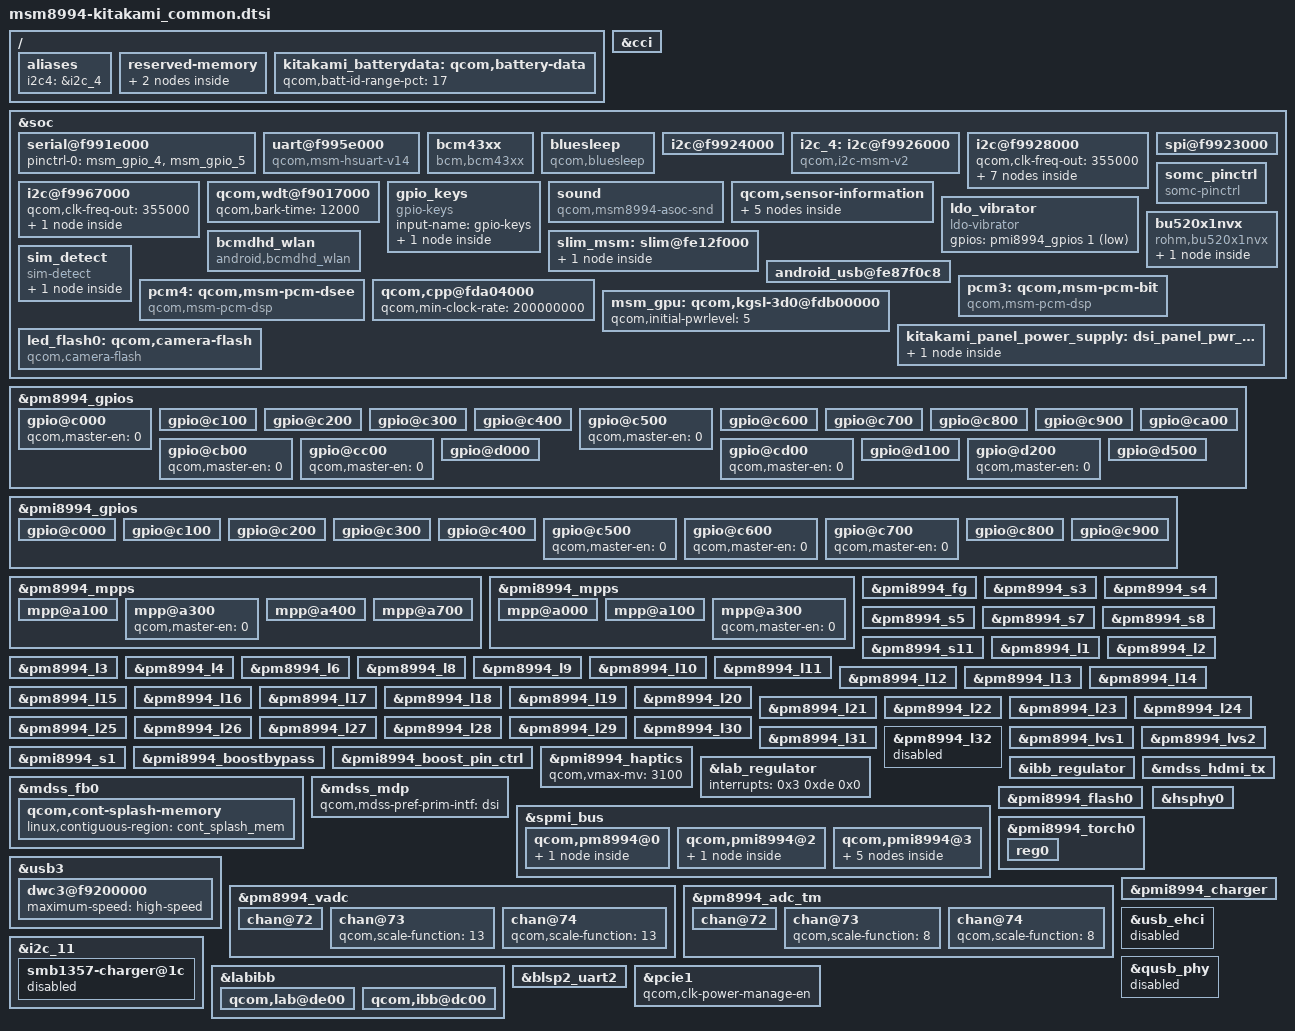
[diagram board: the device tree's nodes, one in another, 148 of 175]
/* arch/arm/boot/dts/qcom/msm8994-kitakami_common.dtsi
 *
 * This program is free software; you can redistribute it and/or modify
 * it under the terms of the GNU General Public License version 2 and
 * only version 2 as published by the Free Software Foundation.
 *
 * This program is distributed in the hope that it will be useful,
 * but WITHOUT ANY WARRANTY; without even the implied warranty of
 * MERCHANTABILITY or FITNESS FOR A PARTICULAR PURPOSE.  See the
 * GNU General Public License for more details.
 */
/*
 * Copyright (C) 2014 Sony Mobile Communications Inc.
 *
 * This program is free software; you can redistribute it and/or modify
 * it under the terms of the GNU General Public License version 2, as
 * published by the Free Software Foundation.
 */

/ {
	aliases {
		i2c4 = &i2c_4;
	};

	reserved-memory {
		fb_mem: fb_region@0 {
			reg = <0 0x40000000 0 0x1000000>;
			label = "fb_mem";
		};

		ramoops_mem: ramoops_region@0 {
			compatible = "removed-dma-pool";
			reg = <0 0x1fe00000 0 0x00200000>;
			no-map;
		};
	};
};

#include "msm8994-kitakami_pinctrl.dtsi"

&cci {
	/delete-node/ qcom,eeprom@0;
	/delete-node/ qcom,eeprom@1;

	/delete-node/ qcom,actuator@0;
	/delete-node/ qcom,actuator@1;

	/delete-node/ qcom,ois@0;

	/delete-node/ qcom,camera@0;
	/delete-node/ qcom,camera@1;
	/delete-node/ qcom,camera@2;
};

&soc {
	/* UART: BLSP2 */
	serial@f991e000 {
		pinctrl-0 = <&msm_gpio_4 &msm_gpio_5>;
		status = "ok";
	};

	/* UART: BLSP8 */
	uart@f995e000 {
		compatible = "qcom,msm-hsuart-v14";
		reg = <0xf995e000 0x1000>,
		      <0xf9944000 0x19000>;
		reg-names = "core_mem", "bam_mem";
		interrupt-names = "core_irq", "bam_irq";
		#address-cells = <0>;
		interrupt-parent = <&blsp2_uart2>;
		interrupts = <0 1>;
		#interrupt-cells = <1>;
		interrupt-map-mask = <0xffffffff>;
		interrupt-map = <0 &intc 0 114 0
				1 &intc 0 239 0>;
		qcom,bam-tx-ep-pipe-index = <2>;
		qcom,bam-rx-ep-pipe-index = <3>;
		pinctrl-names = "default", "sleep";
		pinctrl-0 = <&msm_gpio_45_act &msm_gpio_46_act &msm_gpio_47_act &msm_gpio_48_act>;
		pinctrl-1 = <&msm_gpio_45_sus &msm_gpio_46_sus &msm_gpio_47_sus &msm_gpio_48_sus>;
		qcom,msm-obs;
		status = "ok";
	};

	bcm43xx {
		compatible = "bcm,bcm43xx";
		gpios = <&msm_gpio 91 0x00>, /* BT_REG_ON */
			<&msm_gpio 110 0x00>; /* BT_DEV_WAKE */
		pinctrl-names = "default", "sleep";
		pinctrl-0 = <&msm_gpio_91_act &msm_gpio_110_act>;
		pinctrl-1 = <&msm_gpio_91_sus &msm_gpio_110_sus>;
	};

	bluesleep {
		compatible = "qcom,bluesleep";
		bt_ext_wake = <&msm_gpio 110 0>;
		bt_host_wake = <&msm_gpio 111 0>;
		bt_reg_on = <&msm_gpio 91 0>;
		interrupt-parent = <&msm_gpio>;
		interrupts = <111 0>;
		interrupt-names = "host_wake";
		pinctrl-names = "default", "sleep";
		pinctrl-0 = <&msm_gpio_91_act &msm_gpio_110_act &msm_gpio_111_act>;
		pinctrl-1 = <&msm_gpio_91_sus &msm_gpio_110_sus &msm_gpio_111_sus>;
	};

	/* I2C : BLSP2 */
	i2c@f9924000 {
		qcom,clk-freq-out = <355000>;
		qcom,disable-dma;
		status = "ok";

		/delete-node/ synaptics@20;
	};

	/* I2C : BLSP4 */
	i2c_4: i2c@f9926000 {
		compatible = "qcom,i2c-msm-v2";
		#address-cells = <1>;
		#size-cells = <0>;
		reg-names = "qup_phys_addr", "bam_phys_addr";
		reg = <0xf9926000 0x1000>,
		      <0xf9904000 0x19000>;
		interrupt-names = "qup_irq", "bam_irq";
		interrupts = <0 98 0>, <0 238 0>;
		qcom,clk-freq-out = <355000>;
		qcom,clk-freq-in  = <19200000>;
		clock-names = "iface_clk", "core_clk";
		clocks = <&clock_gcc clk_gcc_blsp1_ahb_clk>,
			 <&clock_gcc clk_gcc_blsp1_qup4_i2c_apps_clk>;

		pinctrl-names = "i2c_active", "i2c_sleep";
		pinctrl-0 = <&i2c_4_active>;
		pinctrl-1 = <&i2c_4_sleep>;
		qcom,noise-rjct-scl = <0>;
		qcom,noise-rjct-sda = <0>;
		qcom,bam-pipe-idx-cons = <18>;
		qcom,bam-pipe-idx-prod = <19>;
		qcom,master-id = <86>;
		status = "ok";
	};

	/* I2C : BLSP6 */
	i2c@f9928000 {
		qcom,clk-freq-out = <355000>;
		status = "ok";
		synaptics_clearpad@2c {
			compatible = "synaptics,clearpad";
			reg = <0x2c>;
			interrupt-parent = <&msm_gpio>;
			interrupts = <42 0x2>;
			touch_vdd-supply = <&pm8994_l22>;
			touch_vio-supply = <&pm8994_s4>;
			synaptics,irq_gpio = <&msm_gpio 42 0x00>;
			synaptics,reset_gpio = <&msm_gpio 109 0x00>;
			chip_id = <0x38>;
			num_sensor_rx = <29>;
			num_sensor_tx = <16>;
			flip_config = <0>;
			default_reporting_mode = <0>;
			rezero_on_init = <0>;
			reset_on_init = <1>;
			force_cal_on_resume = <1>;
			charger_supported = <0>;
			pen_supported = <0>;
			glove_supported = <1>;
			cover_supported = <1>;
			touch_pressure_enabled = <1>;
			touch_size_enabled = <0>;
			touch_orientation_enabled = <0>;
			preset_x_max = <1079>;
			preset_y_max = <1919>;
			preset_n_fingers = <10>;
			synaptics,use-pinctrl;
			pinctrl-names = "irq_gpio-active", "irq_gpio-suspend",
					"reset_gpio-active", "reset_gpio-suspend",
					"reset_gpio-reset";
			pinctrl-0 = <&msm_gpio_42_act>;
			pinctrl-1 = <&msm_gpio_42_sus>;
			pinctrl-2 = <&msm_gpio_109_act>;
			pinctrl-3 = <&msm_gpio_109_sus>;
			pinctrl-4 = <&msm_gpio_109_res>;
			delay_on_hw_reset = <0>;
			delay_after_hw_reset = <200>;
			delay_on_gpio_reset = <400>;
			wakeup_gesture_supported = <1>;
			wakeup_gesture_large_panel = <0>;
			wakeup_gesture_lpm_disabled = <1>;
			wakeup_gesture_timeout = <2000>;
			wakeup_gesture {
				double_tap {
					gesture_code = <0x0003>;
					event_00 {
						type = <2>; /* LOG */
						message = "=== DOUBLE TAP ===";
					};
					event_01 {
						type = <1>; /* KEY */
						code = <116>; /* KEY_POWER */
						down = <1>;
					};
					event_02 {
						type = <1>; /* KEY */
						code = <116>; /* KEY_POWER */
						down = <0>;
					};
					event_03 {
						type = <99>; /* END */
					};
				};
			};
		};

		/delete-node/ nfc-nci@e;
	};

	/* I2C : BLSP11 */
	i2c@f9967000 {
		qcom,clk-freq-out = <355000>;
		status = "ok";

		sii8620@72 {
			compatible = "qcom,mhl-sii8620";
			reg = <0x72>;
			interrupt-parent = <&msm_gpio>;
			mhl-intr-gpio = <&msm_gpio 57 0>;
			mhl-rst-gpio = <&msm_gpio 62 0>;
			mhl-fw-wake-gpio = <&msm_gpio 31 0>;
			mhl-switch-sel-1-gpio = <&pmi8994_gpios 9 0>;
			mhl-switch-sel-2-gpio = <&pmi8994_gpios 10 0>;
			mhl-clk-gpio = <&pm8994_gpios 17 0>;
			clocks = <&clock_rpm clk_div_clk3>;
			clock-names = "mhl_clk";
			mhl_vcc-supply = <&pm8994_l25>;
			qcom,hdmi-tx-map = <&mdss_hdmi_tx>;
		};

		/delete-node/ silabs4705@11;
	};

	/* SPI : BLSP1 */
	spi@f9923000 {
		pinctrl-0 = <&spi0_default>;
		pinctrl-1 = <&spi0_sleep>;
		qcom,shared;
		status = "ok";
	};

	qcom,wdt@f9017000 {
		qcom,bark-time = <12000>;
	};

	gpio_keys {
		compatible = "gpio-keys";
		input-name = "gpio-keys";

		vol_dn {
			label = "volume_down";
			gpios = <&pm8994_gpios 2 0x1>;
			linux,input-type = <1>;
			linux,code = <114>;
			gpio-key,wakeup;
			debounce-interval = <15>;
		};
	};

	sound {
		compatible = "qcom,msm8994-asoc-snd";
		qcom,model = "msm8994-tomtom-snd-card";
		reg = <0xfe034000 0x4>,
		      <0xfe035000 0x4>,
		      <0xfe036000 0x4>,
		      <0xfe037000 0x4>;
		reg-names = "lpaif_pri_mode_muxsel",
			    "lpaif_sec_mode_muxsel",
			    "lpaif_tert_mode_muxsel",
			    "lpaif_quat_mode_muxsel";

		qcom,audio-routing =
			"AIF4 VI", "MCLK",
			"RX_BIAS", "MCLK",
			"LDO_H", "MCLK",
			"MADINPUT", "MCLK",
			"AMIC1", "LDO_H",
			"LDO_H", "AHC ISNS",
			"AMIC2", "MIC BIAS2 External",
			"MIC BIAS2 External", "Headset Mic",
			"MIC BIAS2 External", "ANCRight Headset Mic",
			"AMIC3", "MIC BIAS3 External",
			"MIC BIAS3 External", "ANCLeft Headset Mic",
			"AMIC4", "LDO_H",
			"LDO_H", "AHC VSNS",
			"DMIC1", "MIC BIAS1 External",
			"MIC BIAS1 External", "Digital Mic1",
			"DMIC2", "MIC BIAS1 External",
			"MIC BIAS1 External", "Digital Mic2";
		clock-names = "osr_clk";
		clocks = <&clock_rpm clk_div_clk1>;
		qcom,cdc-mclk-gpios = <&pm8994_gpios 15 0>;
		qcom,tomtom-mclk-clk-freq = <9600000>;
		pinctrl-names = "sleep",
				"auxpcm-active",
				"mi2s-active",
				"active";
		pinctrl-0 = <&pri_mi2s_sleep>, <&pri_mi2s_sd0_sleep>,
				<&sec_aux_pcm_sleep>, <&sec_aux_pcm_din_sleep>;
		pinctrl-1 = <&pri_mi2s_sleep>, <&pri_mi2s_sd0_sleep>,
				<&sec_aux_pcm_active>, <&sec_aux_pcm_din_active>;
		pinctrl-2 = <&pri_mi2s_active>, <&pri_mi2s_sd0_active>,
				<&sec_aux_pcm_sleep>, <&sec_aux_pcm_din_sleep>;
		pinctrl-3 = <&pri_mi2s_active>, <&pri_mi2s_sd0_active>,
				<&sec_aux_pcm_active>, <&sec_aux_pcm_din_active>;
		qcom,ear-en-gpios = <&pm8994_gpios 22 0>;
		qcom,mbhc-audio-jack-type = "5-pole-jack";

		qcom,hdmi-audio-rx;
	};

	qcom,sensor-information {
		/* msm_therm */
		qcom,sensor-information@17 {
			qcom,scaling-factor = <10>;
		};

		/* emmc_therm */
		qcom,sensor-information@18 {
			qcom,scaling-factor = <10>;
		};

		/* quiet_therm */
		qcom,sensor-information@21 {
			qcom,alias-name = "bl_therm";
		};

		sensor_information100: qcom,sensor-information@100 {
			qcom,sensor-type = "adc";
			qcom,sensor-name = "bms";
			qcom,alias-name = "batt_therm";
			qcom,scaling-factor = <1000>;
		};

		sensor_information101: qcom,sensor-information@101 {
			qcom,sensor-type = "adc";
			qcom,sensor-name = "xo_therm";
		};
	};

	ldo_vibrator {
		compatible = "ldo-vibrator";
		gpios = <&pmi8994_gpios 1 1>;
	};

	bcmdhd_wlan {
		compatible = "android,bcmdhd_wlan";
		gpios = <&msm_gpio 113 0x00>, /* WL_REG_ON */
			<&msm_gpio 108 0x00>; /* WL_HOST_WAKE */
		pinctrl-names = "default", "sleep";
		pinctrl-0 = <&msm_gpio_113_act &msm_gpio_108_act>;
		pinctrl-1 = <&msm_gpio_113_sus &msm_gpio_108_sus>;
		wlan-pci-number = <1>;
	};

	somc_pinctrl: somc_pinctrl {
		compatible = "somc-pinctrl";
		pinctrl-names = "platform_common_default",
				"product_common_default",
				"variant_default";
		pinctrl-0 = <&msm_gpio_0 &msm_gpio_1 &msm_gpio_2 &msm_gpio_3 &msm_gpio_4
			     &msm_gpio_5 &msm_gpio_6 &msm_gpio_7 &msm_gpio_8 &msm_gpio_9
			     &msm_gpio_10 &msm_gpio_11 &msm_gpio_12 &msm_gpio_13 &msm_gpio_14
			     &msm_gpio_15 &msm_gpio_16 &msm_gpio_17 &msm_gpio_18 &msm_gpio_19
			     &msm_gpio_20 &msm_gpio_21 &msm_gpio_22 &msm_gpio_23 &msm_gpio_24
			     &msm_gpio_25 &msm_gpio_26 &msm_gpio_27 &msm_gpio_28 &msm_gpio_29
			     &msm_gpio_30 &msm_gpio_31 &msm_gpio_38 &msm_gpio_39 &msm_gpio_40
			     &msm_gpio_41 &msm_gpio_42 &msm_gpio_43 &msm_gpio_44 &msm_gpio_45
			     &msm_gpio_46 &msm_gpio_47 &msm_gpio_48 &msm_gpio_52 &msm_gpio_53
			     &msm_gpio_54 &msm_gpio_55 &msm_gpio_56 &msm_gpio_57 &msm_gpio_58
			     &msm_gpio_59 &msm_gpio_60 &msm_gpio_61 &msm_gpio_62 &msm_gpio_63
			     &msm_gpio_64 &msm_gpio_69 &msm_gpio_74 &msm_gpio_75 &msm_gpio_76
			     &msm_gpio_77 &msm_gpio_78 &msm_gpio_83 &msm_gpio_84 &msm_gpio_85
			     &msm_gpio_86 &msm_gpio_87 &msm_gpio_88 &msm_gpio_89 &msm_gpio_90
			     &msm_gpio_91 &msm_gpio_92 &msm_gpio_93 &msm_gpio_94 &msm_gpio_95
			     &msm_gpio_96 &msm_gpio_100 &msm_gpio_102 &msm_gpio_103 &msm_gpio_104
			     &msm_gpio_105 &msm_gpio_106 &msm_gpio_107 &msm_gpio_108 &msm_gpio_109
			     &msm_gpio_110 &msm_gpio_111 &msm_gpio_112 &msm_gpio_113 &msm_gpio_114
			     &msm_gpio_122>;


		/* If product common default setting is needed,
		   fill pinctrl-1 value in <product>_common.dtsi */
		pinctrl-1 = <>;

		/* If variant specific default setting is needed,
		   fill pinctrl-2 value in <variant>.dtsi */
		pinctrl-2 = <>;
	};

	bu520x1nvx {
		compatible = "rohm,bu520x1nvx";

		acc_cover {
			label = "lid";
			gpios = <&pm8994_gpios 11 0x1>;
			lid-pin = <1>;
			debounce-interval = <50>;
		};
	};
	slim_msm: slim@fe12f000 {
		tomtom_codec {
			qcom,cdc-dmic-sample-rate = <2400000>;
			qcom,cdc-dmic_clk_drv_strength = <2>;
		};
	};

	android_usb@fe87f0c8 {
		/delete-property/ qcom,android-usb-uicc-nluns;
	};

	sim_detect {
		compatible = "sim-detect";
		interrupt-parent = <&msm_gpio>;
		interrupts = <100 0>;

		sim1_det {
			label = "sim-detection";
			pinctrl-names = "tlmm_gpio_key_active",
					"tlmm_gpio_key_suspend";
			pinctrl-0 = <&msm_gpio_100_act>;
			pinctrl-1 = <&msm_gpio_100_sus>;
			gpios = <&msm_gpio 100 0x0>;
			debounce-interval = <10>;
		};
	};
	pcm3: qcom,msm-pcm-bit {
		compatible = "qcom,msm-pcm-dsp";
		qcom,msm-pcm-dsp-id = <3>;
		qcom,msm-pcm-bit;
	};

	pcm4: qcom,msm-pcm-dsee {
		compatible = "qcom,msm-pcm-dsp";
		qcom,msm-pcm-dsp-id = <4>;
		qcom,msm-pcm-bit;
	};
	qcom,cpp@fda04000 {
		qcom,min-clock-rate = <200000000>;
	};

        msm_gpu: qcom,kgsl-3d0@fdb00000 {
                qcom,initial-pwrlevel = <3>;
	};

	kitakami_panel_power_supply: dsi_panel_pwr_supply {
		#address-cells = <1>;
		#size-cells = <0>;
		qcom,panel-supply-entry@0 {
			reg = <0>;
			qcom,supply-name = "vdd";
			qcom,supply-min-voltage = <1800000>;
			qcom,supply-max-voltage = <1800000>;
			qcom,supply-enable-load = <100000>;
			qcom,supply-disable-load = <100>;
			qcom,supply-post-on-sleep = <5>;
		};
/*
		qcom,panel-supply-entry@1 {
			reg = <1>;
			qcom,supply-name = "lab";
			qcom,supply-min-voltage = <5100000>;
			qcom,supply-max-voltage = <5100000>;
			qcom,supply-enable-load = <100000>;
			qcom,supply-disable-load = <100>;
		};

		qcom,panel-supply-entry@2 {
			reg = <2>;
			qcom,supply-name = "ibb";
			qcom,supply-min-voltage = <5100000>;
			qcom,supply-max-voltage = <5100000>;
			qcom,supply-enable-load = <100000>;
			qcom,supply-disable-load = <100>;
			qcom,supply-post-on-sleep = <20>;
		};*/
	};

	led_flash0: qcom,camera-flash {
		cell-index = <0>;
		compatible = "qcom,camera-flash";
		qcom,flash-type = <1>;
		qcom,flash-source = <&pmi8994_flash0 &pmi8994_flash1>;
		qcom,torch-source = <&pmi8994_torch0 &pmi8994_torch1>;
	};

	/delete-node/ qcom,cnss@06300000;
};

&pm8994_gpios {
	/* GPIO_1: NC */
	gpio@c000 {
		qcom,master-en = <0>;		/* Disable */
		status = "ok";
	};

	/* GPIO_2: VOL_DOWN_N */
	gpio@c100 {
		qcom,src-sel = <0>;		/* GPIO */
		qcom,mode = <0>;		/* In */
		qcom,vin-sel = <2>;		/* S4 */
		qcom,pull = <0>;		/* PU */
		qcom,master-en = <1>;		/* Enable */
		status = "ok";
	};

	/* GPIO_3: VOL_UP_N */
	gpio@c200 {
		qcom,src-sel = <0>;		/* GPIO */
		qcom,mode = <0>;		/* In */
		qcom,vin-sel = <2>;		/* S4 */
		qcom,pull = <0>;		/* PU */
		qcom,master-en = <1>;		/* Enable */
		status = "ok";
	};

	/* GPIO_4: SNAPSHOT_N */
	gpio@c300 {
		qcom,src-sel = <0>;		/* GPIO */
		qcom,mode = <0>;		/* In */
		qcom,vin-sel = <2>;		/* S4 */
		qcom,pull = <0>;		/* PU */
		qcom,master-en = <1>;		/* Enable */
		status = "ok";
	};

	/* GPIO_5: FOCUS_N */
	gpio@c400 {
		qcom,src-sel = <0>;		/* GPIO */
		qcom,mode = <0>;		/* In */
		qcom,vin-sel = <2>;		/* S4 */
		qcom,pull = <0>;		/* PU */
		qcom,master-en = <1>;		/* Enable */
		status = "ok";
	};

	/* GPIO_6: NC */
	gpio@c500 {
		qcom,master-en = <0>;		/* Disable */
		status = "ok";
	};

	/* GPIO_7: NFC_VEN */
	gpio@c600 {
		qcom,src-sel = <0>;		/* GPIO */
		qcom,mode = <1>;		/* Out */
		qcom,output-type = <0>;		/* CMOS */
		qcom,vin-sel = <2>;		/* S4 */
		qcom,out-strength = <1>;	/* Low */
		qcom,invert = <0>;		/* Low */
		qcom,master-en = <1>;		/* Enable */
		status = "ok";
	};

	/* GPIO_8: SD_CARD_DET1_N */
	gpio@c700 {
		qcom,src-sel = <0>;		/* GPIO */
		qcom,mode = <0>;		/* In */
		qcom,vin-sel = <2>;		/* S4 */
		qcom,pull = <5>;		/* NP */
		qcom,master-en = <1>;		/* Enable */
		status = "ok";
	};

	/* GPIO_9: TUNER_INT */
	gpio@c800 {
		qcom,src-sel = <0>;		/* GPIO */
		qcom,mode = <0>;		/* In */
		qcom,vin-sel = <2>;		/* S4 */
		qcom,pull = <4>;		/* PD */
		qcom,master-en = <1>;		/* Enable */
		status = "ok";
	};

	/* GPIO_10: NFC_CLK_REQ */
	gpio@c900 {
		qcom,src-sel = <0>;		/* GPIO */
		qcom,mode = <0>;		/* In */
		qcom,vin-sel = <2>;		/* S4 */
		qcom,pull = <4>;		/* PD */
		qcom,master-en = <1>;		/* Enable */
		status = "ok";
	};

	/* GPIO_11: ACC_COVER_OPEN */
	gpio@ca00 {
		qcom,src-sel = <0>;		/* GPIO */
		qcom,mode = <0>;		/* In */
		qcom,vin-sel = <2>;		/* S4 */
		qcom,pull = <0>;		/* PU */
		qcom,master-en = <1>;		/* Enable */
		status = "ok";
	};

	/* GPIO_12: NC */
	gpio@cb00 {
		qcom,master-en = <0>;		/* Disable */
		status = "ok";
	};

	/* GPIO_13: NC */
	gpio@cc00 {
		qcom,master-en = <0>;		/* Disable */
		status = "ok";
	};

	/* GPIO_14: NC */
	gpio@cd00 {
		qcom,master-en = <0>;		/* Disable */
		status = "ok";
	};

	/* GPIO_15: PM_DIVCLK1 */
	/* Follow QCT */

	/* GPIO_16: PMI_CLK */
	/* Follow QCT */

	/* GPIO_17: DIVCLK3 */
	gpio@d000 {
		qcom,src-sel = <2>;		/* SPECIAL_FUNCTION1 */
		qcom,mode = <1>;		/* Out */
		qcom,output-type = <0>;		/* CMOS */
		qcom,vin-sel = <2>;		/* S4 */
		qcom,out-strength = <1>;	/* Low */
		qcom,invert = <0>;		/* Low */
		qcom,master-en = <1>;		/* Enable */
		status = "ok";
	};

	/* GPIO_18: WL_SLEEP_CLK */
	gpio@d100 {
		qcom,src-sel = <3>;		/* SPECIAL_FUNCTION2 */
		qcom,mode = <1>;		/* Out */
		qcom,output-type = <0>;		/* CMOS */
		qcom,vin-sel = <2>;		/* S4 */
		qcom,out-strength = <1>;	/* Low */
		qcom,invert = <0>;		/* Low */
		qcom,master-en = <1>;		/* Enable */
		status = "ok";
	};

	/* GPIO_19: NC */
	gpio@d200 {
		qcom,master-en = <0>;		/* Disable */
		status = "ok";
	};

	/* GPIO_20: PMI_SPON */
	/* Follow QCT */

	/* GPIO_21: BUA_PMI8994 */
	/* Follow QCT */

	/* GPIO_22: EAR_EN */
	gpio@d500 {
		qcom,src-sel = <0>;		/* GPIO */
		qcom,mode = <1>;		/* Out */
		qcom,output-type = <0>;		/* CMOS */
		qcom,vin-sel = <2>;		/* S4 */
		qcom,out-strength = <1>;	/* Low */
		qcom,invert = <0>;		/* Low */
		qcom,master-en = <1>;		/* Enable */
		status = "ok";
	};
};

&pmi8994_gpios {
	/* GPIO_1: VIB_LDO_EN */
	gpio@c000 {
		qcom,src-sel = <0>;		/* GPIO */
		qcom,mode = <1>;		/* Out */
		qcom,output-type = <0>;		/* CMOS */
		qcom,vin-sel = <2>;		/* S4 */
		qcom,out-strength = <1>;	/* Low */
		qcom,invert = <0>;		/* Low */
		qcom,master-en = <1>;		/* Enable */
		status = "ok";
	};

	/* GPIO_2: CHG_PATH_PRI */
	gpio@c100 {
		qcom,src-sel = <0>;		/* GPIO */
		qcom,mode = <0>;		/* In */
		qcom,vin-sel = <2>;		/* S4 */
		qcom,pull = <5>;		/* NP */
		qcom,master-en = <1>;		/* Enable */
		status = "ok";
	};

	/* GPIO_3: TUNER_ANT_SW_EN */
	gpio@c200 {
		qcom,src-sel = <0>;		/* GPIO */
		qcom,mode = <1>;		/* Out */
		qcom,output-type = <0>;		/* CMOS */
		qcom,vin-sel = <2>;		/* S4 */
		qcom,out-strength = <1>;	/* Low */
		qcom,invert = <0>;		/* Low */
		qcom,master-en = <1>;		/* Enable */
		status = "ok";
	};

	/* GPIO_4: TUNER_ANT_SW1 */
	gpio@c300 {
		qcom,src-sel = <0>;		/* GPIO */
		qcom,mode = <1>;		/* Out */
		qcom,output-type = <0>;		/* CMOS */
		qcom,vin-sel = <2>;		/* S4 */
		qcom,out-strength = <1>;	/* Low */
		qcom,invert = <1>;		/* High */
		qcom,master-en = <1>;		/* Enable */
		status = "ok";
	};

	/* GPIO_5: USB3OTG_VBUS_EN */
	gpio@c400 {
		qcom,src-sel = <0>;		/* GPIO */
		qcom,mode = <1>;		/* Out */
		qcom,output-type = <0>;		/* CMOS */
		qcom,vin-sel = <2>;		/* S4 */
		qcom,out-strength = <1>;	/* Low */
		qcom,invert = <0>;		/* Low */
		qcom,master-en = <1>;		/* Enable */
		status = "ok";
	};

	/* GPIO_6: NC */
	gpio@c500 {
		qcom,master-en = <0>;		/* Disable */
		status = "ok";
	};

	/* GPIO_7: NC */
	gpio@c600 {
		qcom,master-en = <0>;		/* Disable */
		status = "ok";
	};

	/* GPIO_8: NC */
	gpio@c700 {
		qcom,master-en = <0>;		/* Disable */
		status = "ok";
	};

	/* GPIO_9: MHL_SWITCH_SEL_1 */
	gpio@c800 {
		qcom,src-sel = <0>;		/* GPIO */
		qcom,mode = <1>;		/* Out */
		qcom,output-type = <0>;		/* CMOS */
		qcom,vin-sel = <2>;		/* S4 */
		qcom,out-strength = <1>;	/* Low */
		qcom,invert = <0>;		/* Low */
		qcom,master-en = <1>;		/* Enable */
		status = "ok";
	};

	/* GPIO_10: MHL_SWITCH_SEL_2 */
	gpio@c900 {
		qcom,src-sel = <0>;		/* GPIO */
		qcom,mode = <1>;		/* Out */
		qcom,output-type = <0>;		/* CMOS */
		qcom,vin-sel = <2>;		/* S4 */
		qcom,out-strength = <1>;	/* Low */
		qcom,invert = <0>;		/* Low */
		qcom,master-en = <1>;		/* Enable */
		status = "ok";
	};
};

&pm8994_mpps {
	/* MPP_1: SDC_UIM_VBIAS */
	/* Follow QCT */

	/* MPP_2: LCD_ID_ADC */
	mpp@a100 {
		qcom,mode = <4>;		/* AIN */
		qcom,ain-route = <1>;		/* AMUX 6 */
		qcom,master-en = <1>;		/* Enable */
		status = "ok";
	};

	/* MPP_3: VREF_DACX */
	/* Follow QCT */

	/* MPP_4: NC */
	mpp@a300 {
		qcom,master-en = <0>;		/* Disable */
		status = "ok";
	};

	/* MPP_5: USB_THERM */
	mpp@a400 {
		qcom,mode = <4>;		/* AIN */
		qcom,ain-route = <0>;		/* AMUX 5 */
		qcom,master-en = <1>;		/* Enable */
		status = "ok";
	};

	/* MPP_6: AUX_PMIC_VSEL */
	/* Follow QCT */

	/* MPP_7: AUX_PMIC_PON */
	/* Follow QCT */

	/* MPP_8: RF_ID */
	mpp@a700 {
		qcom,mode = <4>;		/* AIN */
		qcom,ain-route = <3>;		/* AMUX 8 */
		qcom,master-en = <1>;		/* Enable */
		status = "ok";
	};
};

&pmi8994_mpps {
	/* MPP_1: USB_ID_DISCHG */
	mpp@a000 {
		qcom,mode = <0>;		/* DIN */
		qcom,vin-sel = <0>;		/* VPH */
		qcom,master-en = <1>;		/* Enable */
		status = "ok";
	};

	/* MPP_2: FLASH_LED_NOW */
	mpp@a100 {
		qcom,mode = <0>;		/* DIN */
		qcom,master-en = <1>;		/* Enable */
		qcom,vin-sel = <2>;		/* 1.8v */
		status = "ok";
	};

	/* MPP_3: PMI_SPON */
	/* Follow QCT */

	/* MPP_4: NC */
	mpp@a300 {
		qcom,master-en = <0>;		/* Disable */
		status = "ok";
	};
};

/{
	kitakami_batterydata: qcom,battery-data {
		qcom,batt-id-range-pct = <17>;
		/delete-node/ qcom,itech-3000mah;
		/delete-node/ qcom,itech-3020mah;
	};
};

&pmi8994_fg {
	qcom,hot-bat-decidegc = <550>;
	qcom,warm-bat-decidegc = <450>;
	qcom,cool-bat-decidegc = <100>;
	qcom,cold-bat-decidegc = <50>;
	qcom,irq-volt-empty-mv = <3100>;
	qcom,fg-cutoff-voltage-mv = <3200>;
	qcom,resume-soc = <0xFD>;
	qcom,ext-sense-type;
	qcom,thermal-coefficients = [EC 85 75 4A FC 35];
	qcom,battery-data = <&kitakami_batterydata>;
	qcom,vbat-estimate-diff-mv = <200>;
	qcom,fg-chg-iterm-ma = <150>;
	qcom,fg-cc-cv-threshold-mv = <4340>;
};

&slim_msm {
	tomtom_codec {
		qcom,cdc-micbias-ldoh-v = <0x3>;
		qcom,cdc-micbias-cfilt1-mv = <1800>;
		qcom,cdc-micbias-cfilt2-mv = <2700>;
		qcom,cdc-micbias-cfilt3-mv = <2700>;
		qcom,cdc-micbias1-cfilt-sel = <0x0>;
		qcom,cdc-micbias2-cfilt-sel = <0x1>;
		qcom,cdc-micbias3-cfilt-sel = <0x2>;
		qcom,cdc-micbias4-cfilt-sel = <0x0>;
		qcom,cdc-micbias1-ext-cap;
		/delete-property/ qcom,cdc-micbias2-ext-cap;
		/delete-property/ qcom,cdc-micbias3-ext-cap;
		/delete-property/ qcom,cdc-micbias4-ext-cap;
	};
};

/* Regulator config */
&pm8994_s3 {
	status = "ok";
};
&pm8994_s4 {
	status = "ok";
};

&pm8994_s5 {
	status = "ok";
};

&pm8994_s7 {
	status = "ok";
};

&pm8994_s8 {
	status = "ok";
};

&pm8994_s11 {
	status = "ok";
};

&pm8994_l1 {
	status = "ok";
};

&pm8994_l2 {
	status = "ok";
};

&pm8994_l3 {
	regulator-min-microvolt = <1000000>;
	regulator-max-microvolt = <1000000>;
	qcom,init-enable = <0>;
	qcom,init-voltage = <1000000>;
	qcom,init-ldo-mode = <1>;
	qcom,init-pin-ctrl-enable = <0>;
	qcom,init-pin-ctrl-mode = <0>;
	status = "ok";
};

&pm8994_l4 {
	status = "ok";
};

&pm8994_l6 {
	status = "ok";
};

&pm8994_l8 {
	status = "ok";
};

&pm8994_l9 {
	status = "ok";
};

&pm8994_l10 {
	status = "ok";
};

&pm8994_l11 {
	status = "ok";
};

&pm8994_l12 {
	status = "ok";
};

&pm8994_l13 {
	status = "ok";
};

&pm8994_l14 {
	regulator-min-microvolt = <1800000>;
	regulator-max-microvolt = <1800000>;
	qcom,init-enable = <0>;
	qcom,init-voltage = <1800000>;
	qcom,init-ldo-mode = <1>;
	qcom,init-pin-ctrl-enable = <0>;
	qcom,init-pin-ctrl-mode = <0>;
	status = "ok";
};

&pm8994_l15 {
	status = "ok";
};

&pm8994_l16 {
	status = "ok";
};

&pm8994_l17 {
	regulator-min-microvolt = <2700000>;
	regulator-max-microvolt = <2700000>;
	qcom,init-enable = <0>;
	qcom,init-voltage = <2700000>;
	qcom,init-ldo-mode = <1>;
	qcom,init-pin-ctrl-enable = <0>;
	qcom,init-pin-ctrl-mode = <0>;
	status = "ok";
};

&pm8994_l18 {
	regulator-min-microvolt = <2850000>;
	regulator-max-microvolt = <2850000>;
	qcom,init-enable = <0>;
	qcom,init-voltage = <2850000>;
	qcom,init-ldo-mode = <1>;
	qcom,init-pin-ctrl-enable = <0>;
	qcom,init-pin-ctrl-mode = <0>;
	status = "ok";
};

&pm8994_l19 {
	regulator-min-microvolt = <2850000>;
	regulator-max-microvolt = <2850000>;
	qcom,init-enable = <0>;
	qcom,init-voltage = <2850000>;
	qcom,init-ldo-mode = <1>;
	qcom,init-pin-ctrl-enable = <0>;
	qcom,init-pin-ctrl-mode = <0>;
	status = "ok";
};

&pm8994_l20 {
	status = "ok";
};

&pm8994_l21 {
	status = "ok";
};

&pm8994_l22 {
	regulator-min-microvolt = <3000000>;
	regulator-max-microvolt = <3000000>;
	qcom,init-enable = <0>;
	qcom,init-voltage = <3000000>;
	qcom,init-ldo-mode = <1>;
	qcom,init-pin-ctrl-enable = <0>;
	qcom,init-pin-ctrl-mode = <0>;
	status = "ok";
};

&pm8994_l23 {
	regulator-min-microvolt = <2800000>;
	regulator-max-microvolt = <2800000>;
	qcom,init-enable = <0>;
	qcom,init-voltage = <2800000>;
	qcom,init-ldo-mode = <1>;
	qcom,init-pin-ctrl-enable = <0>;
	qcom,init-pin-ctrl-mode = <0>;
	status = "ok";
};

&pm8994_l24 {
	status = "ok";
};

&pm8994_l25 {
	regulator-min-microvolt = <1000000>;
	regulator-max-microvolt = <1000000>;
	qcom,init-enable = <0>;
	qcom,init-voltage = <1000000>;
	qcom,init-ldo-mode = <1>;
	qcom,init-pin-ctrl-enable = <0>;
	qcom,init-pin-ctrl-mode = <0>;
	status = "ok";
};

&pm8994_l26 {
	status = "ok";
};

&pm8994_l27 {
	regulator-min-microvolt = <1200000>;
	regulator-max-microvolt = <1200000>;
	qcom,init-enable = <0>;
	qcom,init-voltage = <1200000>;
	qcom,init-ldo-mode = <1>;
	qcom,init-pin-ctrl-enable = <0>;
	qcom,init-pin-ctrl-mode = <0>;
	status = "ok";
};

&pm8994_l28 {
	status = "ok";
};

&pm8994_l29 {
	regulator-min-microvolt = <2700000>;
	regulator-max-microvolt = <2700000>;
	qcom,init-enable = <0>;
	qcom,init-voltage = <2700000>;
	qcom,init-ldo-mode = <1>;
	qcom,init-pin-ctrl-enable = <0>;
	qcom,init-pin-ctrl-mode = <0>;
	status = "ok";
};

&pm8994_l30 {
	qcom,init-enable = <0>;
	qcom,send-defaults;
	status = "ok";
};

&pm8994_l31 {
	status = "ok";
};

&pm8994_l32 {
	status = "disabled";
};

&pm8994_lvs1 {
	qcom,init-enable = <0>;
	qcom,init-pin-ctrl-enable = <0>;
	qcom,init-pin-ctrl-mode = <0>;
	status = "ok";
};

&pm8994_lvs2 {
	qcom,init-enable = <0>;
	qcom,init-pin-ctrl-enable = <0>;
	qcom,init-pin-ctrl-mode = <0>;
	status = "ok";
};

&pmi8994_s1 {
	status = "ok";
};

&pmi8994_boostbypass {
	status = "ok";
};

&pmi8994_boost_pin_ctrl {
	status = "ok";
};

&pmi8994_haptics {
	status = "ok";
	qcom,vmax-mv = <3100>;
};

&lab_regulator {
	interrupts = <0x3 0xde 0x0>;
	interrupt-names = "lab_vreg_not_ok_interrupt";
};

&ibb_regulator {
	interrupts = <0x3 0xdc 0x0>;
	interrupt-names = "ibb_vreg_not_ok_interrupt";
	qcom,qpnp-ibb-slew-rate = <2000000>;
};

/* GPU overrides */
&msm_gpu {
        qcom,initial-pwrlevel = <5>;
};

&mdss_fb0 {
	linux,contiguous-region = <&fb_mem>;

	/* Kernel splash configuration */
	qcom,memblock-reserve = <0x03401000 0x2200000>;
	qcom,memory-reservation-size = <0x1000000>; /* size: 16MB */
	qcom,mdss-fb-splash-logo-enabled;
	qcom,cont-splash-memory {
		linux,contiguous-region = <&cont_splash_mem>;
	};
};

&mdss_mdp {
	qcom,mdss-pref-prim-intf = "dsi";
};

&mdss_hdmi_tx {
	pinctrl-names = "hdmi_hpd_active", "hdmi_ddc_active",
				"hdmi_active", "hdmi_sleep";
	pinctrl-0 = <&mdss_hdmi_hpd_active &mdss_hdmi_ddc_suspend>;
	pinctrl-1 = <&mdss_hdmi_hpd_active &mdss_hdmi_ddc_active>;
	pinctrl-2 = <&mdss_hdmi_hpd_active &mdss_hdmi_ddc_active>;
	pinctrl-3 = <&mdss_hdmi_hpd_suspend &mdss_hdmi_ddc_suspend>;
};

&spmi_bus {
	qcom,pm8994@0 {
		qcom,power-on@800 {
			qcom,s3-debounce = <8>;
			qcom,s3-src = "resin";
			/delete-node/ qcom,pon_2;
		};
	};

	qcom,pmi8994@2 {
		qcom,power-on@800 {
			qcom,s3-debounce = <128>;
			qcom,s3-src = "kpdpwr-and-resin";
		};
	};
};

&spmi_bus {
	qcom,pmi8994@3 {
		qcom,leds@d000 {
			qcom,rgb_0 {
				qcom,start-idx = <1>;
				qcom,ramp-step-ms = <120>;
				qcom,duty-pcts = [00 00 00 00 00
						00 00 00 00 00
						50 00 00 00 00
						00 00 00 00 00
						00];
				qcom,use-blink;
			};

			qcom,rgb_1 {
				qcom,start-idx = <1>;
				qcom,ramp-step-ms = <120>;
				qcom,duty-pcts = [00 00 00 00 00
						00 00 00 00 00
						50 00 00 00 00
						00 00 00 00 00
						00];
				qcom,use-blink;
			};

			qcom,rgb_2 {
				qcom,start-idx = <1>;
				qcom,ramp-step-ms = <120>;
				qcom,duty-pcts = [00 00 00 00 00
						00 00 00 00 00
						50 00 00 00 00
						00 00 00 00 00
						00];
				qcom,use-blink;
			};
		};
		qcom,leds@d300 {
			/* Kitakami platform-wide configuration */
			qcom,pmic-charger-support;
			qcom,self-check-enabled;
			qcom,headroom = <400>;
			qcom,startup-dly = <128>;
			qcom,clamp-current = <165>; /* 13.03mA */

			/* Not supported (by choice) features */
			/delete-node/ qcom,thermal-derate-enabled;
			/delete-node/ qcom,thermal-derate-threshold;
			/delete-node/ qcom,thermal-derate-rate;
			/delete-node/ qcom,current-ramp-enabled;
			/delete-node/ qcom,ramp_up_step;
			/delete-node/ qcom,ramp_dn_step;
			/delete-node/ qcom,headroom-sense-ch0-enabled;
			/delete-node/ qcom,headroom-sense-ch1-enabled;
			/delete-node/ qcom,power-detect-enabled;

			/* Warning: Explicitly disabled by SoMC */
			/delete-node/ qcom,vph-pwr-droop-enabled;
		};
	};
};

// /delete-node/ &pmi8994_flash1;

&pmi8994_flash0 {
	qcom,max-current = <1000>;
	qcom,current = <1000>;
	qcom,id = <1>;
};

&pmi8994_torch0 {
	qcom,max-current = <200>;
	qcom,current = <200>;
	qcom,id = <1>;
	qcom,torch-enable;
	reg0 {
		regulator-name = "pmi8994_boostbypass";
		max-voltage = <3600000>;
	};

};

&usb3 {
	qcom,usb_dp-vadc = <&pmi8994_vadc>;
	qcom,usb_dm-vadc = <&pmi8994_vadc>;
	mhl_switch_sel1_gpio = <&pmi8994_gpios 9 0>;
	mhl_switch_sel2_gpio = <&pmi8994_gpios 10 0>;
	vbus_rec-supply = <&smbcharger_charger_otg>;
	dwc3@f9200000 {
		maximum-speed = "high-speed";
	};
};

&hsphy0 {
	qcom,hsphy-init = <0x00FBDFA7>;
	qcom,hsphy-init-host = <0x00FBD1A7>;
};

&pm8994_vadc {
	chan@72 {
		label = "xo_therm";
		reg = <0x72>;
		qcom,decimation = <0>;
		qcom,pre-div-channel-scaling = <0>;
		qcom,calibration-type = "ratiometric";
		qcom,scale-function = <4>;
		qcom,hw-settle-time = <2>;
		qcom,fast-avg-setup = <0>;
	};
	chan@73 { /* msm_therm */
		qcom,scale-function = <13>;
	};
	chan@74 { /* emmc_therm */
		qcom,scale-function = <13>;
	};
};

&pm8994_adc_tm {
	chan@72 {
		label = "xo_therm";
		reg = <0x72>;
		qcom,decimation = <0>;
		qcom,pre-div-channel-scaling = <0>;
		qcom,calibration-type = "ratiometric";
		qcom,scale-function = <2>;
		qcom,hw-settle-time = <2>;
		qcom,fast-avg-setup = <0>;
		qcom,btm-channel-number = <0x88>;
		qcom,thermal-node;
	};
	chan@73 { /* msm_therm */
		qcom,scale-function = <8>;
	};
	chan@74 { /* emmc_therm */
		qcom,scale-function = <8>;
	};
};

&i2c_11 {
	smb1357-charger@1c {
		status = " disabled";
	};
};

&pmi8994_charger {
	/delete-property/ qcom,parallel-usb-min-current-ma;
	/delete-property/ qcom,parallel-9v-usb-min-current-ma;
	qcom,bmd-pin-src = "bpd_none";
	qcom,chg-vadc = <&pmi8994_vadc>;
	qcom,charge-unknown-battery;
	qcom,dc-psy-type = "Wireless";
	somc,thermal-mitigation-usb-5v = <1500 1500 1500 1500 1500 1500 1500 1500 1200 900 700 500 300 300 0>;
	somc,thermal-mitigation-usb-9v = <1800 1800 1800 1800 1800 1800 1400 1000 700 500 400 300 300 300 0>;
	somc,thermal-mitigation-dc-5v = <1000 1000 1000 900 800 700 700 700 700 700 700 500 300 300 0>;
	gpio_id_low = <&pmi8994_mpps 1 0>;
	qcom,autoadjust-vfloat;
};

&usb_ehci {
	status = "disabled";
	/delete-property/ qcom,usb2-enable-uicc;
};

&qusb_phy {
	status = "disabled";
};

&labibb {
	qcom,lab@de00 {
		qcom,qpnp-lab-init-voltage = <6000000>;
		qcom,qpnp-lab-init-lcd-voltage = <6000000>;
	};
	qcom,ibb@dc00 {
		qcom,qpnp-ibb-init-voltage = <6000000>;
		qcom,qpnp-ibb-init-lcd-voltage = <6000000>;
		qcom,qpnp-ibb-discharge-resistor = <16>;
		qcom,qpnp-ibb-lab-pwrup-delay = <8000>;
		qcom,qpnp-ibb-lab-pwrdn-delay = <1000>;
	};
};

&blsp2_uart2 {
	/delete-property/ qcom,inject-rx-on-wakeup;
	/delete-property/ qcom,rx-char-to-inject;
};

&pcie1 {
	qcom,clk-power-manage-en;
};
